# S3C2440A register map
Vendor: Samsung; Series: S3C2440; File version: 1.0
Samsung S3C2440A ARM920T-based Microprocessor for FriendlyARM Mini2440 Development Board
CPU: ARM920T r1p1, little endian, MPU, no FPU, 0 interrupt priority bits
Registers are 32-bit, read-write, reset 0x0 unless marked. A register's access mark holds for its fields unless they carry their own. Offsets are from the block's base; lines under a group give offsets from that group; [hi:lo] are bit positions; {n}, {i} and the like mark numbered series; 'fields as' and 'values as' point back to an identical list; <NAME> marks a mode.

## Memory map
0x48000000 MEMCON size 0x5C — Memory Controller
0x49000000 USBHOST size 0x400 — USB Host Controller
0x4A000000 INTC size 0x100 — Interrupt Controller
0x4B000000 DMA size 0x100 — Direct Memory Access Controller
0x4C000000 CLKPWR size 0x40 — Clock & Power Management
0x4D000000 LCDC size 0x100 — LCD Controller
0x4E000000 NFCON size 0x20 — NAND Flash Controller
0x50000000 UART0 size 0x2C
0x50004000 UART1 size 0x2C
0x50008000 UART2 size 0x2C
0x51000000 PWM size 0x40 — PWM Timer
0x52000140 USBD size 0x200 — USB Device Controller
0x53000000 WDT size 0x10 — Watchdog Timer
0x54000000 I2C size 0x10 — I2C Controller
0x55000000 IIS size 0x14 — IIS Audio Interface
0x56000000 GPIO size 0x100 — General Purpose I/O
0x57000000 RTC size 0x50 — Real Time Clock
0x58000000 ADC size 0x20 — ADC and Touch Screen Interface
0x59000000 SPI0 size 0x20
0x59000020 SPI1 size 0x20
0x5A000000 SDI size 0x100 — SD Interface

## MEMCON — Memory Controller
Base 0x48000000
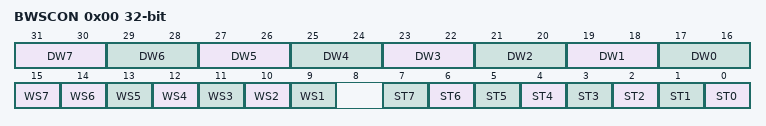
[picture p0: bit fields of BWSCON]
0x00 BWSCON — Bus Width & Wait Status Control Register
  [31:30] DW7 — Bank7 bus width (00=8-bit, 01=16-bit, 10=32-bit)
  [2n+17:2n+16] DW{n} (n=0..6) — Bank{n} bus width
  [15] WS7 — Bank7 WAIT status enable (0=disable, 1=enable)
  [n+8] WS{n} (n=1..6) — Bank{n} WAIT status enable
  [7] ST7 — Bank7 SRAM type (0=not using UB/LB, 1=using UB/LB)
  [n] ST{n} (n=0..6) — Bank{n} SRAM type
{0x4+4i} BANKCON{i} reset 0x700 (i=0..5) — Bank {i} Control Register
0x1C BANKCON6 reset 0x18008 — Bank 6 Control Register
0x20 BANKCON7 reset 0x18008 — Bank 7 Control Register
0x24 REFRESH — SDRAM Refresh Control Register
0x28 BANKSIZE — Flexible Bank Size Register
0x2C MRSRB6 reset 0x30 — Mode Register Set for Bank6
0x30 MRSRB7 reset 0x30 — Mode Register Set for Bank7

## INTC — Interrupt Controller
Base 0x4A000000
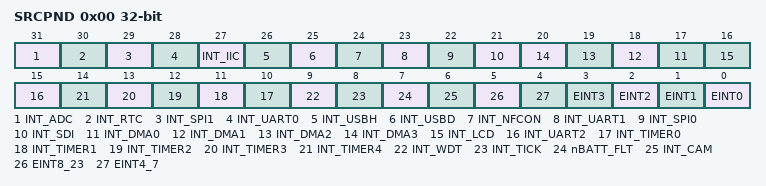
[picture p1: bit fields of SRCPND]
0x00 SRCPND — Interrupt Source Pending Register
  [31] INT_ADC — ADC and Touch Screen interrupt (1=pending)
  [30] INT_RTC — RTC alarm interrupt (1=pending)
  [29] INT_SPI1 — SPI1 interrupt (1=pending)
  [28] INT_UART0 — UART0 interrupt (1=pending)
  [27] INT_IIC — IIC interrupt (1=pending)
  [26] INT_USBH — USB Host interrupt (1=pending)
  [25] INT_USBD — USB Device interrupt (1=pending)
  [24] INT_NFCON — NAND Flash Controller interrupt (1=pending)
  [23] INT_UART1 — UART1 interrupt (1=pending)
  [22] INT_SPI0 — SPI0 interrupt (1=pending)
  [21] INT_SDI — SD Interface interrupt (1=pending)
  [n+17] INT_DMA{n} (n=0..3) — DMA channel {n} interrupt (1=pending)
  [16] INT_LCD — LCD interrupt (1=pending)
  [15] INT_UART2 — UART2 interrupt (1=pending)
  [n+10] INT_TIMER{n} (n=0..4) — Timer{n} interrupt (1=pending)
  [9] INT_WDT — Watchdog Timer interrupt (1=pending)
  [8] INT_TICK — RTC Time Tick interrupt (1=pending)
  [7] nBATT_FLT — Battery Fault interrupt (1=pending)
  [6] INT_CAM — Camera Interface interrupt (1=pending)
  [5] EINT8_23 — External interrupt 8~23 (1=pending)
  [4] EINT4_7 — External interrupt 4~7 (1=pending)
  [n] EINT{n} (n=0..3) — External interrupt {n} (1=pending)
0x04 INTMOD — Interrupt Mode Register
0x08 INTMSK reset 0xFFFFFFFF — Interrupt Mask Register
0x0C PRIORITY — IRQ Priority Control Register
0x10 INTPND — Interrupt Pending Register
0x14 INTOFFSET ro — Interrupt Offset Register
0x18 SUBSRCPND — Sub Source Pending Register
0x1C INTSUBMSK reset 0x7 — Interrupt Sub Mask Register

## DMA — Direct Memory Access Controller
Base 0x4B000000
0x00 DISRC0 — DMA 0 Initial Source Address
0x04 DISRCC0 — DMA 0 Source Control
0x08 DIDST0 — DMA 0 Initial Destination Address
0x0C DIDSTC0 — DMA 0 Destination Control
0x10 DCON0 — DMA 0 Control
0x14 DSTAT0 ro — DMA 0 Status
0x18 DCSRC0 ro — DMA 0 Current Source Address
0x1C DCDST0 ro — DMA 0 Current Destination Address
